VERSION ""

NS_ :

BS_:

BU_: TIRETEMP CART BMS ACC LV INV

BO_ 3221225472 VECTOR__INDEPENDENT_SIG_MSG: 0 Vector__XXX
 SG_ LV_Fault_Count : 0|8@1+ (1,0) [0|0] "" Vector__XXX
 SG_ LV_Pedals_Fault : 0|8@1- (1,0) [0|0] "" Vector__XXX

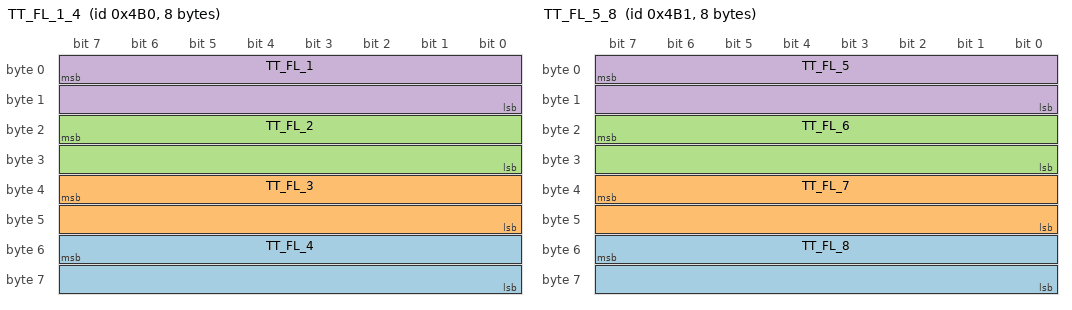
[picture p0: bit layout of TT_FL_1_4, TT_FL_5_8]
BO_ 1200 TT_FL_1_4: 8 TIRETEMP
 SG_ TT_FL_4 : 55|16@0+ (0.1,-100) [-100|6453.5] "temperature:C" Vector__XXX
 SG_ TT_FL_3 : 39|16@0+ (0.1,-100) [-100|6453.5] "temperature:C" Vector__XXX
 SG_ TT_FL_2 : 23|16@0+ (0.1,-100) [-100|6453.5] "temperature:C" Vector__XXX
 SG_ TT_FL_1 : 7|16@0+ (0.1,-100) [-100|6453.5] "temperature:C" Vector__XXX

BO_ 1201 TT_FL_5_8: 8 TIRETEMP
 SG_ TT_FL_8 : 55|16@0+ (0.1,-100) [-100|6453.5] "temperature:C" Vector__XXX
 SG_ TT_FL_7 : 39|16@0+ (0.1,-100) [-100|6453.5] "temperature:C" Vector__XXX
 SG_ TT_FL_6 : 23|16@0+ (0.1,-100) [-100|6453.5] "temperature:C" Vector__XXX
 SG_ TT_FL_5 : 7|16@0+ (0.1,-100) [-100|6453.5] "temperature:C" Vector__XXX

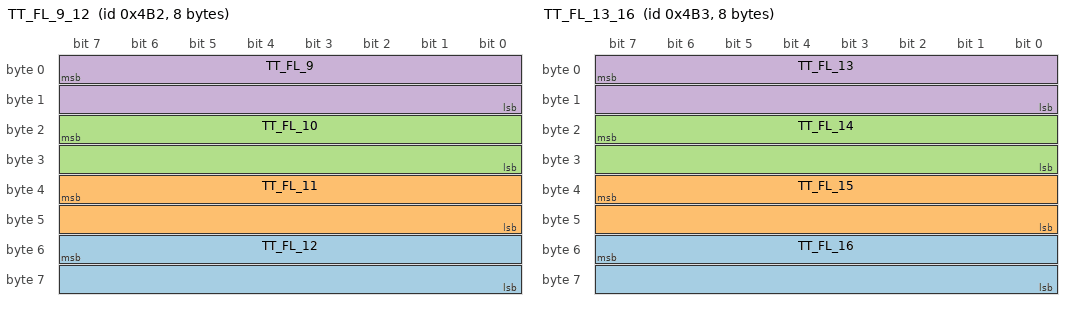
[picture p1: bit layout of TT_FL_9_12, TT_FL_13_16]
BO_ 1202 TT_FL_9_12: 8 TIRETEMP
 SG_ TT_FL_12 : 55|16@0+ (0.1,-100) [-100|6453.5] "temperature:C" Vector__XXX
 SG_ TT_FL_11 : 39|16@0+ (0.1,-100) [-100|6453.5] "temperature:C" Vector__XXX
 SG_ TT_FL_10 : 23|16@0+ (0.1,-100) [-100|6453.5] "temperature:C" Vector__XXX
 SG_ TT_FL_9 : 7|16@0+ (0.1,-100) [-100|6453.5] "temperature:C" Vector__XXX

BO_ 1203 TT_FL_13_16: 8 TIRETEMP
 SG_ TT_FL_16 : 55|16@0+ (0.1,-100) [-100|6453.5] "temperature:C" Vector__XXX
 SG_ TT_FL_15 : 39|16@0+ (0.1,-100) [-100|6453.5] "temperature:C" Vector__XXX
 SG_ TT_FL_14 : 23|16@0+ (0.1,-100) [-100|6453.5] "temperature:C" Vector__XXX
 SG_ TT_FL_13 : 7|16@0+ (0.1,-100) [-100|6453.5] "temperature:C" Vector__XXX

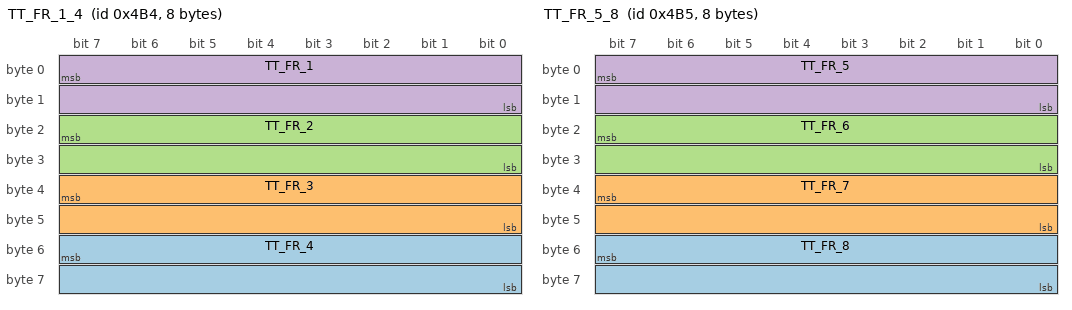
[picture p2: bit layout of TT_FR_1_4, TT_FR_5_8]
BO_ 1204 TT_FR_1_4: 8 TIRETEMP
 SG_ TT_FR_4 : 55|16@0+ (0.1,-100) [-100|6453.5] "temperature:C" Vector__XXX
 SG_ TT_FR_3 : 39|16@0+ (0.1,-100) [-100|6453.5] "temperature:C" Vector__XXX
 SG_ TT_FR_2 : 23|16@0+ (0.1,-100) [-100|6453.5] "temperature:C" Vector__XXX
 SG_ TT_FR_1 : 7|16@0+ (0.1,-100) [-100|6453.5] "temperature:C" Vector__XXX

BO_ 1205 TT_FR_5_8: 8 TIRETEMP
 SG_ TT_FR_8 : 55|16@0+ (0.1,-100) [-100|6453.5] "temperature:C" Vector__XXX
 SG_ TT_FR_7 : 39|16@0+ (0.1,-100) [-100|6453.5] "temperature:C" Vector__XXX
 SG_ TT_FR_6 : 23|16@0+ (0.1,-100) [-100|6453.5] "temperature:C" Vector__XXX
 SG_ TT_FR_5 : 7|16@0+ (0.1,-100) [-100|6453.5] "temperature:C" Vector__XXX

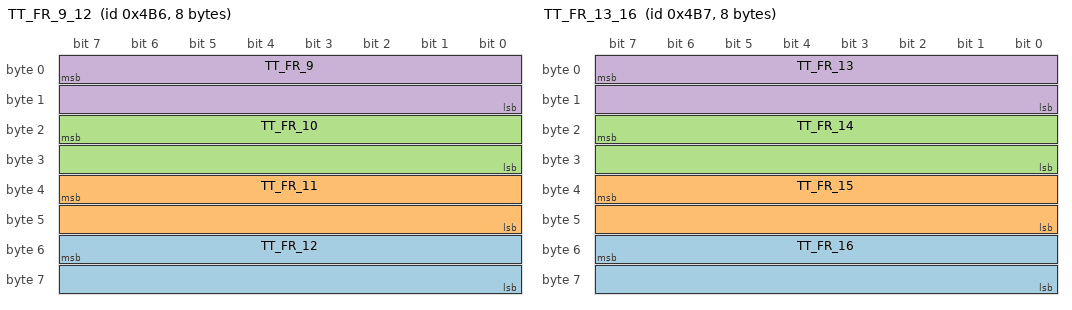
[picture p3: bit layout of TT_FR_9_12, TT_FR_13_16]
BO_ 1206 TT_FR_9_12: 8 TIRETEMP
 SG_ TT_FR_12 : 55|16@0+ (0.1,-100) [-100|6453.5] "temperature:C" Vector__XXX
 SG_ TT_FR_11 : 39|16@0+ (0.1,-100) [-100|6453.5] "temperature:C" Vector__XXX
 SG_ TT_FR_10 : 23|16@0+ (0.1,-100) [-100|6453.5] "temperature:C" Vector__XXX
 SG_ TT_FR_9 : 7|16@0+ (0.1,-100) [-100|6453.5] "temperature:C" Vector__XXX

BO_ 1207 TT_FR_13_16: 8 TIRETEMP
 SG_ TT_FR_16 : 55|16@0+ (0.1,-100) [-100|6453.5] "temperature:C" Vector__XXX
 SG_ TT_FR_15 : 39|16@0+ (0.1,-100) [-100|6453.5] "temperature:C" Vector__XXX
 SG_ TT_FR_14 : 23|16@0+ (0.1,-100) [-100|6453.5] "temperature:C" Vector__XXX
 SG_ TT_FR_13 : 7|16@0+ (0.1,-100) [-100|6453.5] "temperature:C" Vector__XXX

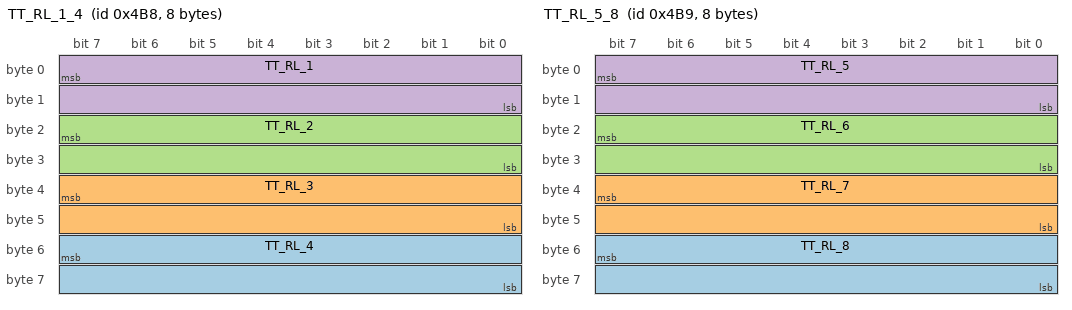
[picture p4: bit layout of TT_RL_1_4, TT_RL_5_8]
BO_ 1208 TT_RL_1_4: 8 TIRETEMP
 SG_ TT_RL_4 : 55|16@0+ (0.1,-100) [-100|6453.5] "temperature:C" Vector__XXX
 SG_ TT_RL_3 : 39|16@0+ (0.1,-100) [-100|6453.5] "temperature:C" Vector__XXX
 SG_ TT_RL_2 : 23|16@0+ (0.1,-100) [-100|6453.5] "temperature:C" Vector__XXX
 SG_ TT_RL_1 : 7|16@0+ (0.1,-100) [-100|6453.5] "temperature:C" Vector__XXX

BO_ 1209 TT_RL_5_8: 8 TIRETEMP
 SG_ TT_RL_8 : 55|16@0+ (0.1,-100) [-100|6453.5] "temperature:C" Vector__XXX
 SG_ TT_RL_7 : 39|16@0+ (0.1,-100) [-100|6453.5] "temperature:C" Vector__XXX
 SG_ TT_RL_6 : 23|16@0+ (0.1,-100) [-100|6453.5] "temperature:C" Vector__XXX
 SG_ TT_RL_5 : 7|16@0+ (0.1,-100) [-100|6453.5] "temperature:C" Vector__XXX

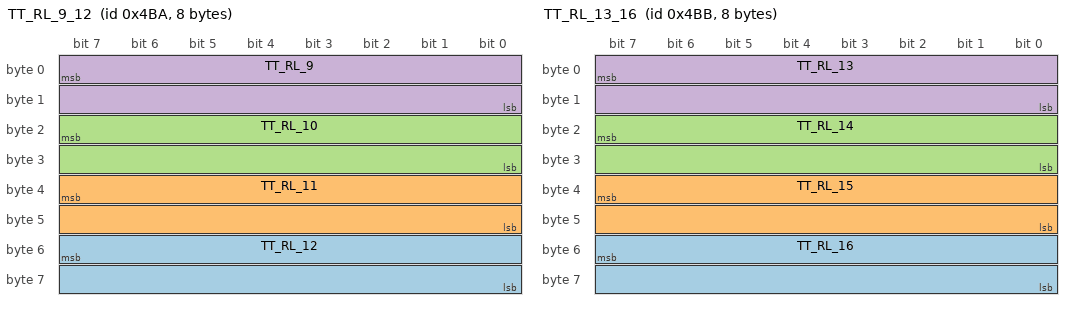
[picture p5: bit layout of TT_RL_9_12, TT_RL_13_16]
BO_ 1210 TT_RL_9_12: 8 TIRETEMP
 SG_ TT_RL_12 : 55|16@0+ (0.1,-100) [-100|6453.5] "temperature:C" Vector__XXX
 SG_ TT_RL_11 : 39|16@0+ (0.1,-100) [-100|6453.5] "temperature:C" Vector__XXX
 SG_ TT_RL_10 : 23|16@0+ (0.1,-100) [-100|6453.5] "temperature:C" Vector__XXX
 SG_ TT_RL_9 : 7|16@0+ (0.1,-100) [-100|6453.5] "temperature:C" Vector__XXX

BO_ 1211 TT_RL_13_16: 8 TIRETEMP
 SG_ TT_RL_16 : 55|16@0+ (0.1,-100) [-100|6453.5] "temperature:C" Vector__XXX
 SG_ TT_RL_15 : 39|16@0+ (0.1,-100) [-100|6453.5] "temperature:C" Vector__XXX
 SG_ TT_RL_14 : 23|16@0+ (0.1,-100) [-100|6453.5] "temperature:C" Vector__XXX
 SG_ TT_RL_13 : 7|16@0+ (0.1,-100) [-100|6453.5] "temperature:C" Vector__XXX

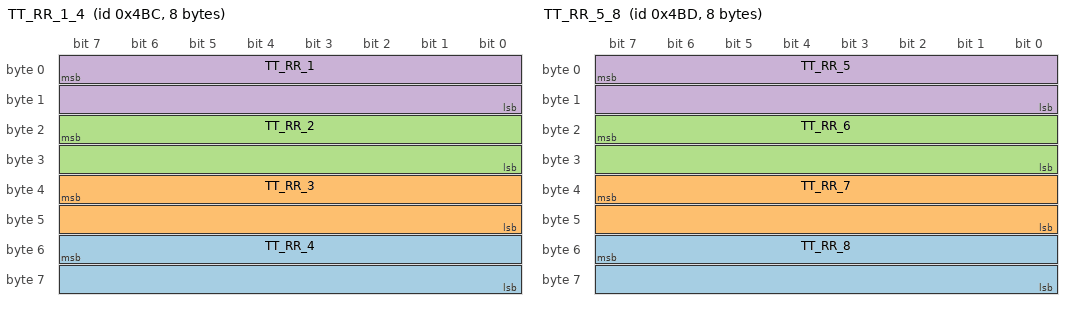
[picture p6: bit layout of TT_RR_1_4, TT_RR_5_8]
BO_ 1212 TT_RR_1_4: 8 TIRETEMP
 SG_ TT_RR_4 : 55|16@0+ (0.1,-100) [-100|6453.5] "temperature:C" Vector__XXX
 SG_ TT_RR_3 : 39|16@0+ (0.1,-100) [-100|6453.5] "temperature:C" Vector__XXX
 SG_ TT_RR_2 : 23|16@0+ (0.1,-100) [-100|6453.5] "temperature:C" Vector__XXX
 SG_ TT_RR_1 : 7|16@0+ (0.1,-100) [-100|6453.5] "temperature:C" Vector__XXX

BO_ 1213 TT_RR_5_8: 8 TIRETEMP
 SG_ TT_RR_8 : 55|16@0+ (0.1,-100) [-100|6453.5] "temperature:C" Vector__XXX
 SG_ TT_RR_7 : 39|16@0+ (0.1,-100) [-100|6453.5] "temperature:C" Vector__XXX
 SG_ TT_RR_6 : 23|16@0+ (0.1,-100) [-100|6453.5] "temperature:C" Vector__XXX
 SG_ TT_RR_5 : 7|16@0+ (0.1,-100) [-100|6453.5] "temperature:C" Vector__XXX

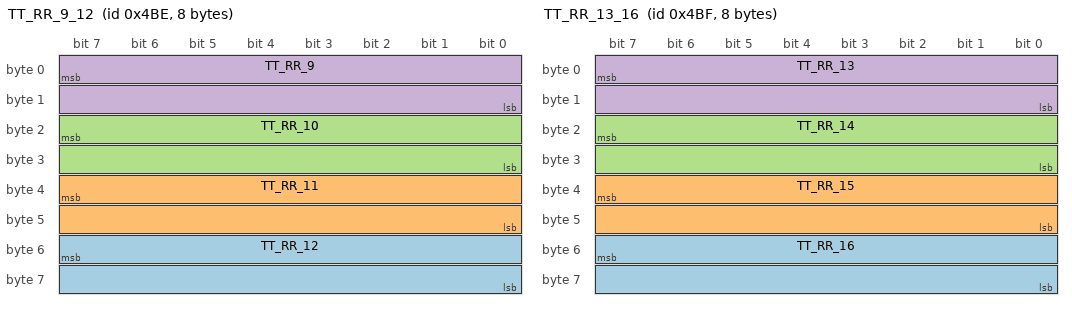
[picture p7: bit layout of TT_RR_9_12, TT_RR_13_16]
BO_ 1214 TT_RR_9_12: 8 TIRETEMP
 SG_ TT_RR_12 : 55|16@0+ (0.1,-100) [-100|6453.5] "temperature:C" Vector__XXX
 SG_ TT_RR_11 : 39|16@0+ (0.1,-100) [-100|6453.5] "temperature:C" Vector__XXX
 SG_ TT_RR_10 : 23|16@0+ (0.1,-100) [-100|6453.5] "temperature:C" Vector__XXX
 SG_ TT_RR_9 : 7|16@0+ (0.1,-100) [-100|6453.5] "temperature:C" Vector__XXX

BO_ 1215 TT_RR_13_16: 8 TIRETEMP
 SG_ TT_RR_16 : 55|16@0+ (0.1,-100) [-100|6453.5] "temperature:C" Vector__XXX
 SG_ TT_RR_15 : 39|16@0+ (0.1,-100) [-100|6453.5] "temperature:C" Vector__XXX
 SG_ TT_RR_14 : 23|16@0+ (0.1,-100) [-100|6453.5] "temperature:C" Vector__XXX
 SG_ TT_RR_13 : 7|16@0+ (0.1,-100) [-100|6453.5] "temperature:C" Vector__XXX

BO_ 4 M004_Charging: 2 LV
 SG_ LV_ACC_Charging_Max_Current : 8|8@1- (1,0) [0|0] "" Vector__XXX
 SG_ LV_ACC_Charging : 0|8@1- (1,0) [0|0] ""  ACC

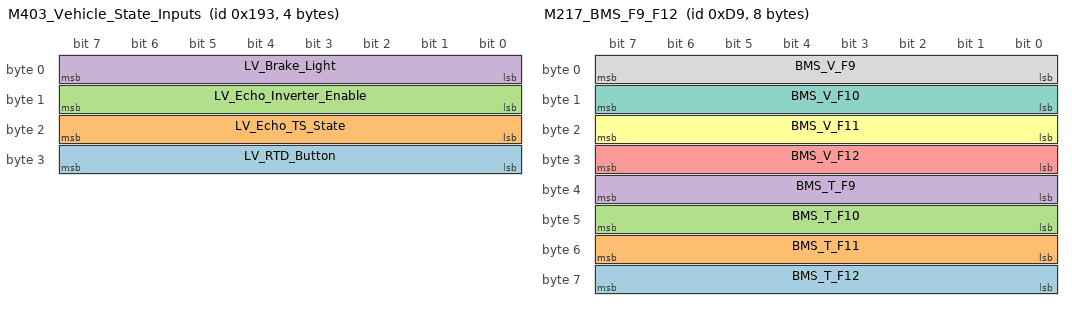
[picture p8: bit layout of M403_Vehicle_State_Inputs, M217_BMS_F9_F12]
BO_ 403 M403_Vehicle_State_Inputs: 4 LV
 SG_ LV_RTD_Button : 24|8@1+ (1,0) [0|0] "" Vector__XXX
 SG_ LV_Echo_TS_State : 16|8@1- (1,0) [0|0] "" Vector__XXX
 SG_ LV_Echo_Inverter_Enable : 8|8@1- (1,0) [0|0] "" Vector__XXX
 SG_ LV_Brake_Light : 0|8@1+ (1,0) [0|0] "" Vector__XXX

BO_ 217 M217_BMS_F9_F12: 8 BMS
 SG_ BMS_T_F12 : 56|8@1+ (0.25,0) [0|63.75] "temperature:C" Vector__XXX
 SG_ BMS_T_F11 : 48|8@1+ (0.25,0) [0|63.75] "temperature:C" Vector__XXX
 SG_ BMS_T_F10 : 40|8@1+ (0.25,0) [0|63.75] "temperature:C" Vector__XXX
 SG_ BMS_T_F9 : 32|8@1+ (0.25,0) [0|63.75] "temperature:C" Vector__XXX
 SG_ BMS_V_F12 : 24|8@1+ (0.01,1.8) [1.8|4.35] "voltage:V" Vector__XXX
 SG_ BMS_V_F11 : 16|8@1+ (0.01,1.8) [1.8|4.35] "voltage:V" Vector__XXX
 SG_ BMS_V_F10 : 8|8@1+ (0.01,1.8) [1.8|4.35] "voltage:V" Vector__XXX
 SG_ BMS_V_F9 : 0|8@1+ (0.01,1.8) [1.8|4.35] "voltage:V" Vector__XXX

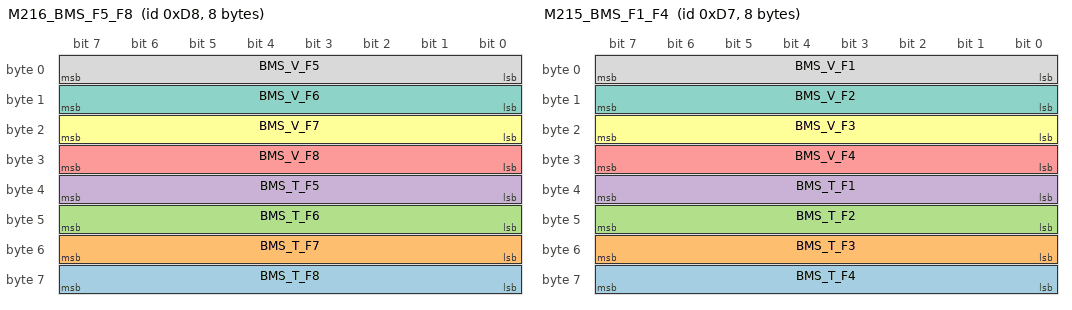
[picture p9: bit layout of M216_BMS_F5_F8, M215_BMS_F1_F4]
BO_ 216 M216_BMS_F5_F8: 8 BMS
 SG_ BMS_T_F8 : 56|8@1+ (0.25,0) [0|63.75] "temperature:C" Vector__XXX
 SG_ BMS_T_F7 : 48|8@1+ (0.25,0) [0|63.75] "temperature:C" Vector__XXX
 SG_ BMS_T_F6 : 40|8@1+ (0.25,0) [0|63.75] "temperature:C" Vector__XXX
 SG_ BMS_T_F5 : 32|8@1+ (0.25,0) [0|63.75] "temperature:C" Vector__XXX
 SG_ BMS_V_F8 : 24|8@1+ (0.01,1.8) [1.8|4.35] "voltage:V" Vector__XXX
 SG_ BMS_V_F7 : 16|8@1+ (0.01,1.8) [1.8|4.35] "voltage:V" Vector__XXX
 SG_ BMS_V_F6 : 8|8@1+ (0.01,1.8) [1.8|4.35] "voltage:V" Vector__XXX
 SG_ BMS_V_F5 : 0|8@1+ (0.01,1.8) [1.8|4.35] "voltage:V" Vector__XXX

BO_ 215 M215_BMS_F1_F4: 8 BMS
 SG_ BMS_T_F4 : 56|8@1+ (0.25,0) [0|63.75] "temperature:C" Vector__XXX
 SG_ BMS_T_F3 : 48|8@1+ (0.25,0) [0|63.75] "temperature:C" Vector__XXX
 SG_ BMS_T_F2 : 40|8@1+ (0.25,0) [0|63.75] "temperature:C" Vector__XXX
 SG_ BMS_T_F1 : 32|8@1+ (0.25,0) [0|63.75] "temperature:C" Vector__XXX
 SG_ BMS_V_F4 : 24|8@1+ (0.01,1.8) [1.8|4.35] "voltage:V" Vector__XXX
 SG_ BMS_V_F3 : 16|8@1+ (0.01,1.8) [1.8|4.35] "voltage:V" Vector__XXX
 SG_ BMS_V_F2 : 8|8@1+ (0.01,1.8) [1.8|4.35] "voltage:V" Vector__XXX
 SG_ BMS_V_F1 : 0|8@1+ (0.01,1.8) [1.8|4.35] "voltage:V" Vector__XXX

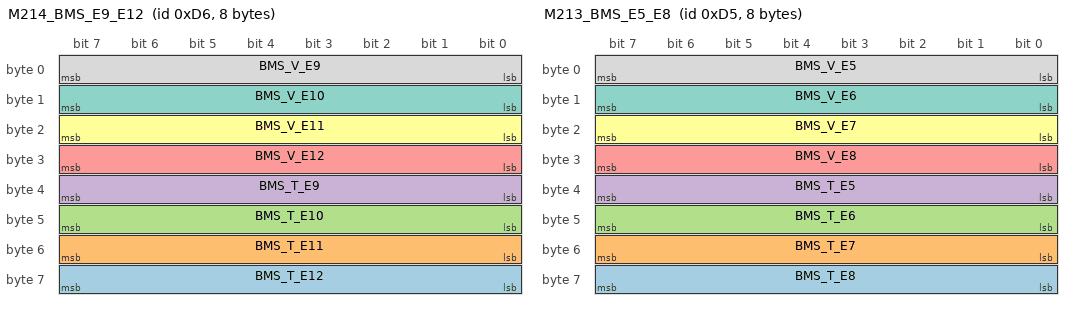
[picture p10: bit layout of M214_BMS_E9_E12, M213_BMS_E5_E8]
BO_ 214 M214_BMS_E9_E12: 8 BMS
 SG_ BMS_T_E12 : 56|8@1+ (0.25,0) [0|63.75] "temperature:C" Vector__XXX
 SG_ BMS_T_E11 : 48|8@1+ (0.25,0) [0|63.75] "temperature:C" Vector__XXX
 SG_ BMS_T_E10 : 40|8@1+ (0.25,0) [0|63.75] "temperature:C" Vector__XXX
 SG_ BMS_T_E9 : 32|8@1+ (0.25,0) [0|63.75] "temperature:C" Vector__XXX
 SG_ BMS_V_E12 : 24|8@1+ (0.01,1.8) [1.8|4.35] "voltage:V" Vector__XXX
 SG_ BMS_V_E11 : 16|8@1+ (0.01,1.8) [1.8|4.35] "voltage:V" Vector__XXX
 SG_ BMS_V_E10 : 8|8@1+ (0.01,1.8) [1.8|4.35] "voltage:V" Vector__XXX
 SG_ BMS_V_E9 : 0|8@1+ (0.01,1.8) [1.8|4.35] "voltage:V" Vector__XXX

BO_ 213 M213_BMS_E5_E8: 8 BMS
 SG_ BMS_T_E8 : 56|8@1+ (0.25,0) [0|63.75] "temperature:C" Vector__XXX
 SG_ BMS_T_E7 : 48|8@1+ (0.25,0) [0|63.75] "temperature:C" Vector__XXX
 SG_ BMS_T_E6 : 40|8@1+ (0.25,0) [0|63.75] "temperature:C" Vector__XXX
 SG_ BMS_T_E5 : 32|8@1+ (0.25,0) [0|63.75] "temperature:C" Vector__XXX
 SG_ BMS_V_E8 : 24|8@1+ (0.01,1.8) [1.8|4.35] "voltage:V" Vector__XXX
 SG_ BMS_V_E7 : 16|8@1+ (0.01,1.8) [1.8|4.35] "voltage:V" Vector__XXX
 SG_ BMS_V_E6 : 8|8@1+ (0.01,1.8) [1.8|4.35] "voltage:V" Vector__XXX
 SG_ BMS_V_E5 : 0|8@1+ (0.01,1.8) [1.8|4.35] "voltage:V" Vector__XXX

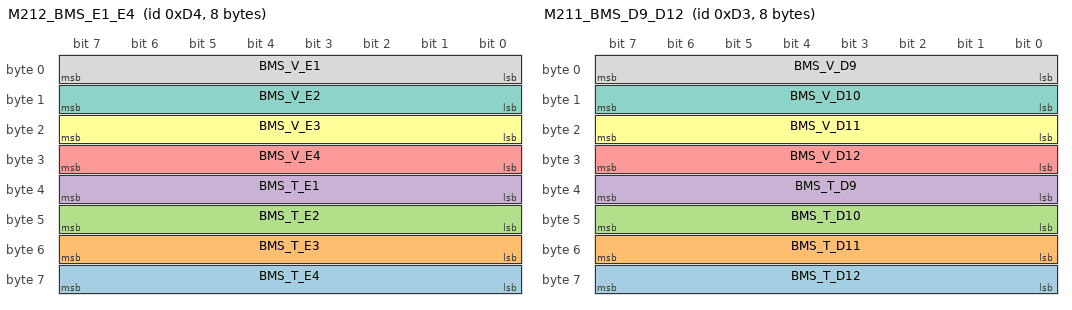
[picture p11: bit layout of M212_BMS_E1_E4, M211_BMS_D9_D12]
BO_ 212 M212_BMS_E1_E4: 8 BMS
 SG_ BMS_T_E4 : 56|8@1+ (0.25,0) [0|63.75] "temperature:C" Vector__XXX
 SG_ BMS_T_E3 : 48|8@1+ (0.25,0) [0|63.75] "temperature:C" Vector__XXX
 SG_ BMS_T_E2 : 40|8@1+ (0.25,0) [0|63.75] "temperature:C" Vector__XXX
 SG_ BMS_T_E1 : 32|8@1+ (0.25,0) [0|63.75] "temperature:C" Vector__XXX
 SG_ BMS_V_E4 : 24|8@1+ (0.01,1.8) [1.8|4.35] "voltage:V" Vector__XXX
 SG_ BMS_V_E3 : 16|8@1+ (0.01,1.8) [1.8|4.35] "voltage:V" Vector__XXX
 SG_ BMS_V_E2 : 8|8@1+ (0.01,1.8) [1.8|4.35] "voltage:V" Vector__XXX
 SG_ BMS_V_E1 : 0|8@1+ (0.01,1.8) [1.8|4.35] "voltage:V" Vector__XXX

BO_ 211 M211_BMS_D9_D12: 8 BMS
 SG_ BMS_T_D12 : 56|8@1+ (0.25,0) [0|63.75] "temperature:C" Vector__XXX
 SG_ BMS_T_D11 : 48|8@1+ (0.25,0) [0|63.75] "temperature:C" Vector__XXX
 SG_ BMS_T_D10 : 40|8@1+ (0.25,0) [0|63.75] "temperature:C" Vector__XXX
 SG_ BMS_T_D9 : 32|8@1+ (0.25,0) [0|63.75] "temperature:C" Vector__XXX
 SG_ BMS_V_D12 : 24|8@1+ (0.01,1.8) [1.8|4.35] "voltage:V" Vector__XXX
 SG_ BMS_V_D11 : 16|8@1+ (0.01,1.8) [1.8|4.35] "voltage:V" Vector__XXX
 SG_ BMS_V_D10 : 8|8@1+ (0.01,1.8) [1.8|4.35] "voltage:V" Vector__XXX
 SG_ BMS_V_D9 : 0|8@1+ (0.01,1.8) [1.8|4.35] "voltage:V" Vector__XXX

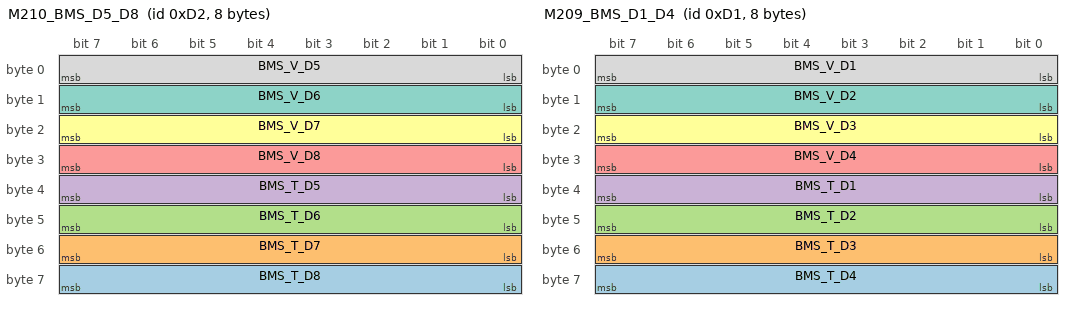
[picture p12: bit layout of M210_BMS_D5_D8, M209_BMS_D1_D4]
BO_ 210 M210_BMS_D5_D8: 8 BMS
 SG_ BMS_T_D8 : 56|8@1+ (0.25,0) [0|63.75] "temperature:C" Vector__XXX
 SG_ BMS_T_D7 : 48|8@1+ (0.25,0) [0|63.75] "temperature:C" Vector__XXX
 SG_ BMS_T_D6 : 40|8@1+ (0.25,0) [0|63.75] "temperature:C" Vector__XXX
 SG_ BMS_T_D5 : 32|8@1+ (0.25,0) [0|63.75] "temperature:C" Vector__XXX
 SG_ BMS_V_D8 : 24|8@1+ (0.01,1.8) [1.8|4.35] "voltage:V" Vector__XXX
 SG_ BMS_V_D7 : 16|8@1+ (0.01,1.8) [1.8|4.35] "voltage:V" Vector__XXX
 SG_ BMS_V_D6 : 8|8@1+ (0.01,1.8) [1.8|4.35] "voltage:V" Vector__XXX
 SG_ BMS_V_D5 : 0|8@1+ (0.01,1.8) [1.8|4.35] "voltage:V" Vector__XXX

BO_ 209 M209_BMS_D1_D4: 8 BMS
 SG_ BMS_T_D4 : 56|8@1+ (0.25,0) [0|63.75] "temperature:C" Vector__XXX
 SG_ BMS_T_D3 : 48|8@1+ (0.25,0) [0|63.75] "temperature:C" Vector__XXX
 SG_ BMS_T_D2 : 40|8@1+ (0.25,0) [0|63.75] "temperature:C" Vector__XXX
 SG_ BMS_T_D1 : 32|8@1+ (0.25,0) [0|63.75] "temperature:C" Vector__XXX
 SG_ BMS_V_D4 : 24|8@1+ (0.01,1.8) [1.8|4.35] "voltage:V" Vector__XXX
 SG_ BMS_V_D3 : 16|8@1+ (0.01,1.8) [1.8|4.35] "voltage:V" Vector__XXX
 SG_ BMS_V_D2 : 8|8@1+ (0.01,1.8) [1.8|4.35] "voltage:V" Vector__XXX
 SG_ BMS_V_D1 : 0|8@1+ (0.01,1.8) [1.8|4.35] "voltage:V" Vector__XXX

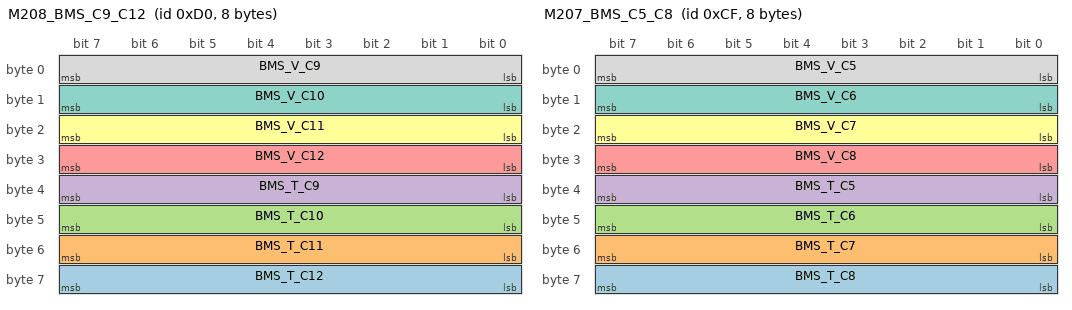
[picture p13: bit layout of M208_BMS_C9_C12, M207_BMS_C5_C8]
BO_ 208 M208_BMS_C9_C12: 8 BMS
 SG_ BMS_T_C12 : 56|8@1+ (0.25,0) [0|63.75] "temperature:C" Vector__XXX
 SG_ BMS_T_C11 : 48|8@1+ (0.25,0) [0|63.75] "temperature:C" Vector__XXX
 SG_ BMS_T_C10 : 40|8@1+ (0.25,0) [0|63.75] "temperature:C" Vector__XXX
 SG_ BMS_T_C9 : 32|8@1+ (0.25,0) [0|63.75] "temperature:C" Vector__XXX
 SG_ BMS_V_C12 : 24|8@1+ (0.01,1.8) [1.8|4.35] "voltage:V" Vector__XXX
 SG_ BMS_V_C11 : 16|8@1+ (0.01,1.8) [1.8|4.35] "voltage:V" Vector__XXX
 SG_ BMS_V_C10 : 8|8@1+ (0.01,1.8) [1.8|4.35] "voltage:V" Vector__XXX
 SG_ BMS_V_C9 : 0|8@1+ (0.01,1.8) [1.8|4.35] "voltage:V" Vector__XXX

BO_ 207 M207_BMS_C5_C8: 8 BMS
 SG_ BMS_T_C8 : 56|8@1+ (0.25,0) [0|63.75] "temperature:C" Vector__XXX
 SG_ BMS_T_C7 : 48|8@1+ (0.25,0) [0|63.75] "temperature:C" Vector__XXX
 SG_ BMS_T_C6 : 40|8@1+ (0.25,0) [0|63.75] "temperature:C" Vector__XXX
 SG_ BMS_T_C5 : 32|8@1+ (0.25,0) [0|63.75] "temperature:C" Vector__XXX
 SG_ BMS_V_C8 : 24|8@1+ (0.01,1.8) [1.8|4.35] "voltage:V" Vector__XXX
 SG_ BMS_V_C7 : 16|8@1+ (0.01,1.8) [1.8|4.35] "voltage:V" Vector__XXX
 SG_ BMS_V_C6 : 8|8@1+ (0.01,1.8) [1.8|4.35] "voltage:V" Vector__XXX
 SG_ BMS_V_C5 : 0|8@1+ (0.01,1.8) [1.8|4.35] "voltage:V" Vector__XXX

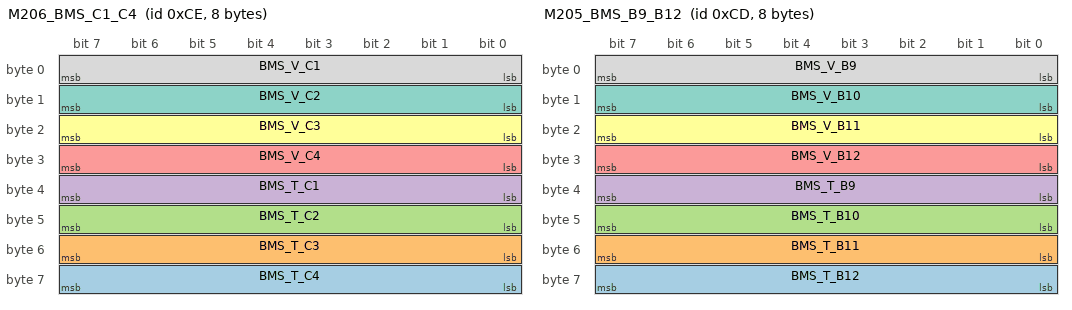
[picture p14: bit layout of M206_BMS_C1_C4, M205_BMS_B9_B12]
BO_ 206 M206_BMS_C1_C4: 8 BMS
 SG_ BMS_T_C4 : 56|8@1+ (0.25,0) [0|63.75] "temperature:C" Vector__XXX
 SG_ BMS_T_C3 : 48|8@1+ (0.25,0) [0|63.75] "temperature:C" Vector__XXX
 SG_ BMS_T_C2 : 40|8@1+ (0.25,0) [0|63.75] "temperature:C" Vector__XXX
 SG_ BMS_T_C1 : 32|8@1+ (0.25,0) [0|63.75] "temperature:C" Vector__XXX
 SG_ BMS_V_C4 : 24|8@1+ (0.01,1.8) [1.8|4.35] "voltage:V" Vector__XXX
 SG_ BMS_V_C3 : 16|8@1+ (0.01,1.8) [1.8|4.35] "voltage:V" Vector__XXX
 SG_ BMS_V_C2 : 8|8@1+ (0.01,1.8) [1.8|4.35] "voltage:V" Vector__XXX
 SG_ BMS_V_C1 : 0|8@1+ (0.01,1.8) [1.8|4.35] "voltage:V" Vector__XXX

BO_ 205 M205_BMS_B9_B12: 8 BMS
 SG_ BMS_T_B12 : 56|8@1+ (0.25,0) [0|63.75] "temperature:C" Vector__XXX
 SG_ BMS_T_B11 : 48|8@1+ (0.25,0) [0|63.75] "temperature:C" Vector__XXX
 SG_ BMS_T_B10 : 40|8@1+ (0.25,0) [0|63.75] "temperature:C" Vector__XXX
 SG_ BMS_T_B9 : 32|8@1+ (0.25,0) [0|63.75] "temperature:C" Vector__XXX
 SG_ BMS_V_B12 : 24|8@1+ (0.01,1.8) [1.8|4.35] "voltage:V" Vector__XXX
 SG_ BMS_V_B11 : 16|8@1+ (0.01,1.8) [1.8|4.35] "voltage:V" Vector__XXX
 SG_ BMS_V_B10 : 8|8@1+ (0.01,1.8) [1.8|4.35] "voltage:V" Vector__XXX
 SG_ BMS_V_B9 : 0|8@1+ (0.01,1.8) [1.8|4.35] "voltage:V" Vector__XXX

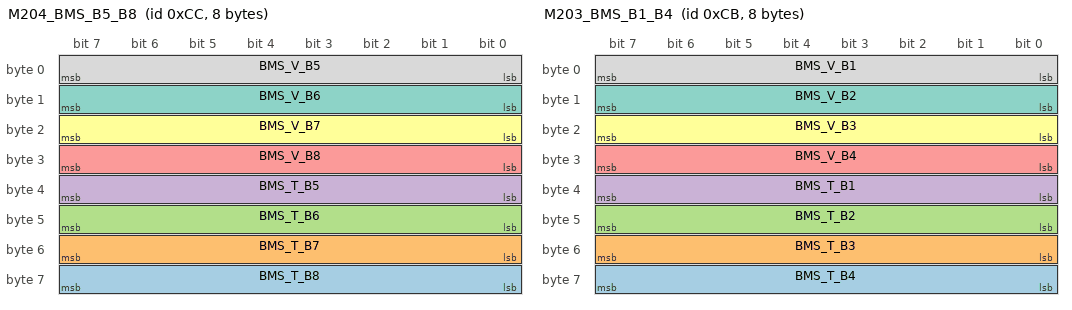
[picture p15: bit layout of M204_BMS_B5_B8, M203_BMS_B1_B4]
BO_ 204 M204_BMS_B5_B8: 8 BMS
 SG_ BMS_T_B8 : 56|8@1+ (0.25,0) [0|63.75] "temperature:C" Vector__XXX
 SG_ BMS_T_B7 : 48|8@1+ (0.25,0) [0|63.75] "temperature:C" Vector__XXX
 SG_ BMS_T_B6 : 40|8@1+ (0.25,0) [0|63.75] "temperature:C" Vector__XXX
 SG_ BMS_T_B5 : 32|8@1+ (0.25,0) [0|63.75] "temperature:C" Vector__XXX
 SG_ BMS_V_B8 : 24|8@1+ (0.01,1.8) [1.8|4.35] "voltage:V" Vector__XXX
 SG_ BMS_V_B7 : 16|8@1+ (0.01,1.8) [1.8|4.35] "voltage:V" Vector__XXX
 SG_ BMS_V_B6 : 8|8@1+ (0.01,1.8) [1.8|4.35] "voltage:V" Vector__XXX
 SG_ BMS_V_B5 : 0|8@1+ (0.01,1.8) [1.8|4.35] "voltage:V" Vector__XXX

BO_ 203 M203_BMS_B1_B4: 8 BMS
 SG_ BMS_T_B4 : 56|8@1+ (0.25,0) [0|63.75] "temperature:C" Vector__XXX
 SG_ BMS_T_B3 : 48|8@1+ (0.25,0) [0|63.75] "temperature:C" Vector__XXX
 SG_ BMS_T_B2 : 40|8@1+ (0.25,0) [0|63.75] "temperature:C" Vector__XXX
 SG_ BMS_T_B1 : 32|8@1+ (0.25,0) [0|63.75] "temperature:C" Vector__XXX
 SG_ BMS_V_B4 : 24|8@1+ (0.01,1.8) [1.8|4.35] "voltage:V" Vector__XXX
 SG_ BMS_V_B3 : 16|8@1+ (0.01,1.8) [1.8|4.35] "voltage:V" Vector__XXX
 SG_ BMS_V_B2 : 8|8@1+ (0.01,1.8) [1.8|4.35] "voltage:V" Vector__XXX
 SG_ BMS_V_B1 : 0|8@1+ (0.01,1.8) [1.8|4.35] "voltage:V" Vector__XXX

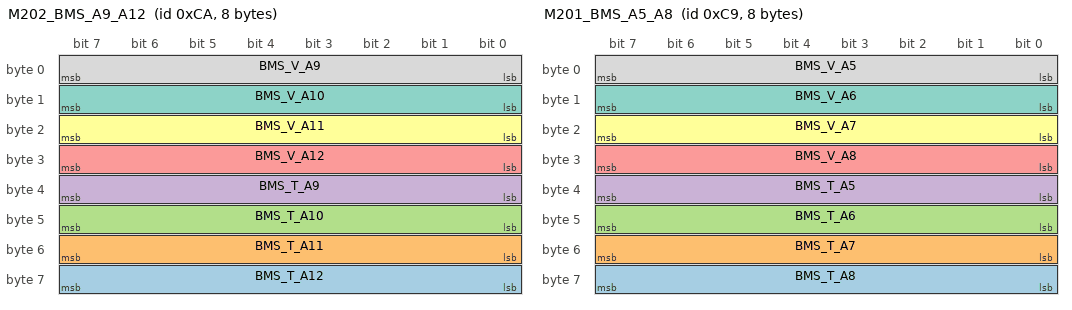
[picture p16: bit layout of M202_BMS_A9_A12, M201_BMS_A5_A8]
BO_ 202 M202_BMS_A9_A12: 8 BMS
 SG_ BMS_T_A12 : 56|8@1+ (0.25,0) [0|63.75] "temperature:C" Vector__XXX
 SG_ BMS_T_A11 : 48|8@1+ (0.25,0) [0|63.75] "temperature:C" Vector__XXX
 SG_ BMS_T_A10 : 40|8@1+ (0.25,0) [0|63.75] "temperature:C" Vector__XXX
 SG_ BMS_T_A9 : 32|8@1+ (0.25,0) [0|63.75] "temperature:C" Vector__XXX
 SG_ BMS_V_A12 : 24|8@1+ (0.01,1.8) [1.8|4.35] "voltage:V" Vector__XXX
 SG_ BMS_V_A11 : 16|8@1+ (0.01,1.8) [1.8|4.35] "voltage:V" Vector__XXX
 SG_ BMS_V_A10 : 8|8@1+ (0.01,1.8) [1.8|4.35] "voltage:V" Vector__XXX
 SG_ BMS_V_A9 : 0|8@1+ (0.01,1.8) [1.8|4.35] "voltage:V" Vector__XXX

BO_ 201 M201_BMS_A5_A8: 8 BMS
 SG_ BMS_T_A8 : 56|8@1+ (0.25,0) [0|63.75] "temperature:C" Vector__XXX
 SG_ BMS_T_A7 : 48|8@1+ (0.25,0) [0|63.75] "temperature:C" Vector__XXX
 SG_ BMS_T_A6 : 40|8@1+ (0.25,0) [0|63.75] "temperature:C" Vector__XXX
 SG_ BMS_T_A5 : 32|8@1+ (0.25,0) [0|63.75] "temperature:C" Vector__XXX
 SG_ BMS_V_A8 : 24|8@1+ (0.01,1.8) [1.8|4.35] "voltage:V" Vector__XXX
 SG_ BMS_V_A7 : 16|8@1+ (0.01,1.8) [1.8|4.35] "voltage:V" Vector__XXX
 SG_ BMS_V_A6 : 8|8@1+ (0.01,1.8) [1.8|4.35] "voltage:V" Vector__XXX
 SG_ BMS_V_A5 : 0|8@1+ (0.01,1.8) [1.8|4.35] "voltage:V" Vector__XXX

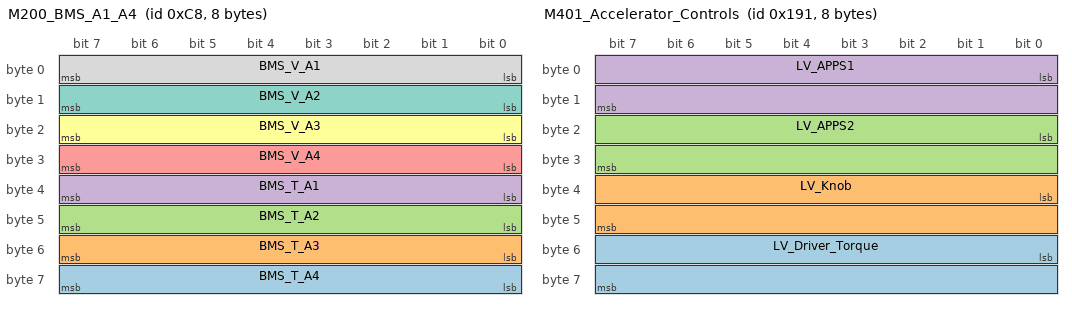
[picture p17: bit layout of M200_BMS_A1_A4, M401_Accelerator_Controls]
BO_ 200 M200_BMS_A1_A4: 8 BMS
 SG_ BMS_T_A4 : 56|8@1+ (0.25,0) [0|63.75] "temperature:C" Vector__XXX
 SG_ BMS_T_A3 : 48|8@1+ (0.25,0) [0|63.75] "temperature:C" Vector__XXX
 SG_ BMS_T_A2 : 40|8@1+ (0.25,0) [0|63.75] "temperature:C" Vector__XXX
 SG_ BMS_T_A1 : 32|8@1+ (0.25,0) [0|63.75] "temperature:C" Vector__XXX
 SG_ BMS_V_A4 : 24|8@1+ (0.01,1.8) [1.8|4.35] "voltage:V" Vector__XXX
 SG_ BMS_V_A3 : 16|8@1+ (0.01,1.8) [1.8|4.35] "voltage:V" Vector__XXX
 SG_ BMS_V_A2 : 8|8@1+ (0.01,1.8) [1.8|4.35] "voltage:V" Vector__XXX
 SG_ BMS_V_A1 : 0|8@1+ (0.01,1.8) [1.8|4.35] "voltage:V" Vector__XXX

BO_ 3 M003_DCDC_Enable: 1 LV
 SG_ LV_ACC_DCDC_Enable : 0|8@1- (1,0) [0|0] ""  ACC

BO_ 2 M002_TS_State: 1 ACC
 SG_ ACC_TS_State : 0|8@1- (1,0) [0|0] ""  LV

BO_ 1 M001_Vehicle_State: 1 LV
 SG_ LV_Vehicle_State : 0|8@1- (1,0) [0|0] "" Vector__XXX

BO_ 402 M402_Brakes_Faults_Display: 7 LV
 SG_ LV_Knob_Tick : 48|8@1+ (0.1,0) [0|25.5] "" Vector__XXX
 SG_ LV_Momentary_Both_Pedals : 47|1@1+ (1,0) [0|1] "" Vector__XXX
 SG_ LV_Momentary_APPS_Implausibility : 46|1@1+ (1,0) [0|1] "" Vector__XXX
 SG_ LV_Momentary_BPT_Upper : 45|1@1+ (1,0) [0|1] "" Vector__XXX
 SG_ LV_Momentary_BPT_Lower : 44|1@1+ (1,0) [0|1] "" Vector__XXX
 SG_ LV_Momentary_APPS2_Upper : 43|1@1+ (1,0) [0|1] "" Vector__XXX
 SG_ LV_Momentary_APPS2_Lower : 42|1@1+ (1,0) [0|1] "" Vector__XXX
 SG_ LV_Momentary_APPS1_Upper : 41|1@1+ (1,0) [0|1] "" Vector__XXX
 SG_ LV_Momentary_APPS1_Lower : 40|1@1+ (1,0) [0|1] "" Vector__XXX
 SG_ LV_Fault_Both_Pedals : 39|1@1+ (1,0) [0|1] "" Vector__XXX
 SG_ LV_Fault_APPS_Implausibility : 38|1@1+ (1,0) [0|1] "" Vector__XXX
 SG_ LV_Fault_BPT_Upper : 37|1@1+ (1,0) [0|1] "" Vector__XXX
 SG_ LV_Fault_BPT_Lower : 36|1@1+ (1,0) [0|1] "" Vector__XXX
 SG_ LV_Fault_APPS2_Upper : 35|1@1+ (1,0) [0|1] "" Vector__XXX
 SG_ LV_Fault_APPS2_Lower : 34|1@1+ (1,0) [0|1] "" Vector__XXX
 SG_ LV_Fault_APPS1_Upper : 33|1@1+ (1,0) [0|1] "" Vector__XXX
 SG_ LV_Fault_APPS1_Lower : 32|1@1+ (1,0) [0|1] "" Vector__XXX
 SG_ LV_BPT_Front : 16|16@1+ (1,0) [0|0] "" Vector__XXX
 SG_ LV_BPT_Rear : 0|16@1+ (1,0) [0|0] "" Vector__XXX

BO_ 401 M401_Accelerator_Controls: 8 LV
 SG_ LV_Driver_Torque : 48|16@1- (0.1,0) [-3276.8|3276.7] "torque:N.m" Vector__XXX
 SG_ LV_Knob : 32|16@1+ (1,0) [0|0] "" Vector__XXX
 SG_ LV_APPS2 : 16|16@1+ (1,0) [0|0] "" Vector__XXX
 SG_ LV_APPS1 : 0|16@1+ (1,0) [0|0] "" Vector__XXX

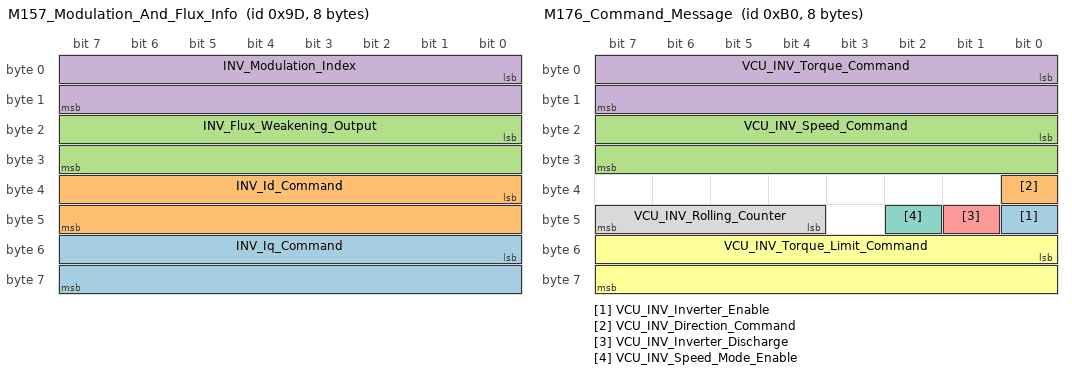
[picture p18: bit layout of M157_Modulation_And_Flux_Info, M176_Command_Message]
BO_ 157 M157_Modulation_And_Flux_Info: 8 INV
 SG_ INV_Iq_Command : 48|16@1- (0.1,0) [-3276.8|3276.7] "current:A" Vector__XXX
 SG_ INV_Id_Command : 32|16@1- (0.1,0) [-3276.8|3276.7] "current:A" Vector__XXX
 SG_ INV_Flux_Weakening_Output : 16|16@1- (0.1,0) [-3276.8|3276.7] "current:A" Vector__XXX
 SG_ INV_Modulation_Index : 0|16@1- (0.0001,0) [-3.2768|3.2767] "" Vector__XXX

BO_ 156 M156_Torque_And_Timer_Info: 8 INV
 SG_ INV_Power_On_Timer : 32|32@1+ (0.003,0) [0|12884800] "time:second" Vector__XXX
 SG_ INV_Torque_Feedback : 16|16@1- (0.1,0) [-3276.8|3276.7] "torque:N.m" Vector__XXX
 SG_ INV_Commanded_Torque : 0|16@1- (0.1,0) [-3276.8|3276.7] "torque:N.m" Vector__XXX

BO_ 178 M178_Read_Write_Param_Response: 8 INV
 SG_ INV_Parameter_Response_Write_OK : 16|1@1+ (1,0) [0|1] "" Vector__XXX
 SG_ INV_Parameter_Response_Data : 32|16@1- (1,0) [-32768|32767] "" Vector__XXX
 SG_ INV_Parameter_Response_Addr : 0|16@1+ (1,0) [0|65535] "" Vector__XXX

BO_ 177 M177_Read_Write_Param_Command: 8 Vector__XXX
 SG_ VCU_INV_Parameter_Data : 32|16@1- (1,0) [-32768|32767] "" Vector__XXX
 SG_ VCU_INV_Parameter_RW_Command : 16|1@1+ (1,0) [0|1] "" Vector__XXX
 SG_ VCU_INV_Parameter_Address : 0|16@1+ (1,0) [0|65535] "" Vector__XXX

BO_ 176 M176_Command_Message: 8 LV
 SG_ VCU_INV_Inverter_Enable : 40|1@1+ (1,0) [0|1] "" Vector__XXX
 SG_ VCU_INV_Direction_Command : 32|1@1+ (1,0) [0|1] "" Vector__XXX
 SG_ VCU_INV_Speed_Command : 16|16@1- (1,0) [-32768|32767] "angular_speed:rpm" Vector__XXX
 SG_ VCU_INV_Torque_Command : 0|16@1- (0.1,0) [-3276.8|3276.7] "torque:N.m" Vector__XXX
 SG_ VCU_INV_Inverter_Discharge : 41|1@1+ (1,0) [0|1] "" Vector__XXX
 SG_ VCU_INV_Torque_Limit_Command : 48|16@1- (0.1,0) [-3276.8|3276.7] "torque:N.m" Vector__XXX
 SG_ VCU_INV_Speed_Mode_Enable : 42|1@1+ (1,0) [0|1] "" Vector__XXX
 SG_ VCU_INV_Rolling_Counter : 44|4@1+ (1,0) [0|15] "" Vector__XXX

BO_ 155 M155_Fault_Codes: 8 INV
 SG_ INV_Run_Fault_Hi : 48|16@1+ (1,0) [0|65535] "" Vector__XXX
 SG_ INV_Post_Fault_Hi : 16|16@1+ (1,0) [0|65535] "" Vector__XXX
 SG_ INV_Run_Fault_Lo : 32|16@1+ (1,0) [0|65535] "" Vector__XXX
 SG_ INV_Post_Fault_Lo : 0|16@1+ (1,0) [0|65535] "" Vector__XXX

BO_ 154 M154_Internal_States: 8 INV
 SG_ INV_Direction_Command : 56|1@1+ (1,0) [0|1] "" Vector__XXX
 SG_ INV_Inverter_Enable_State : 48|1@1+ (1,0) [0|1] ""  LV
 SG_ INV_Relay_3_Status : 26|1@1+ (1,0) [0|1] "" Vector__XXX
 SG_ INV_Relay_4_Status : 27|1@1+ (1,0) [0|1] "" Vector__XXX
 SG_ INV_Relay_2_Status : 25|1@1+ (1,0) [0|1] "" Vector__XXX
 SG_ INV_Inverter_Run_Mode : 32|1@1+ (1,0) [0|1] "" Vector__XXX
 SG_ INV_Inverter_Command_Mode : 40|1@1+ (1,0) [0|1] "" Vector__XXX
 SG_ INV_Relay_1_Status : 24|1@1+ (1,0) [0|1] "" Vector__XXX
 SG_ INV_Inverter_State : 16|8@1+ (1,0) [0|255] "" Vector__XXX
 SG_ INV_VSM_State : 0|8@1+ (1,0) [0|15] "" Vector__XXX
 SG_ INV_Inverter_Enable_Lockout : 55|1@1+ (1,0) [0|1] "" Vector__XXX
 SG_ INV_Inverter_Discharge_State : 37|3@1+ (1,0) [0|7] "" Vector__XXX
 SG_ INV_Relay_5_Status : 28|1@1+ (1,0) [0|1] "" Vector__XXX
 SG_ INV_Relay_6_Status : 29|1@1+ (1,0) [0|1] "" Vector__XXX
 SG_ INV_BMS_Active : 57|1@1+ (1,0) [0|1] "" Vector__XXX
 SG_ INV_BMS_Torque_Limiting : 58|1@1+ (1,0) [0|1] "" Vector__XXX
 SG_ INV_PWM_Frequency : 8|8@1+ (1,0) [0|255] "" Vector__XXX
 SG_ INV_Limit_Max_Speed : 59|1@1+ (1,0) [0|1] "" Vector__XXX
 SG_ INV_Limit_Hot_Spot : 60|1@1+ (1,0) [0|1] "" Vector__XXX
 SG_ INV_Low_Speed_Limiting : 61|1@1+ (1,0) [0|1] "" Vector__XXX
 SG_ INV_Rolling_Counter : 44|4@1+ (1,0) [0|15] "" Vector__XXX
 SG_ INV_Limit_Coolant_Derating : 62|1@1+ (1,0) [0|1] "" Vector__XXX
 SG_ INV_Self_Sensing_Assist_Enable : 33|1@1+ (1,0) [0|1] "" Vector__XXX
 SG_ INV_Limit_Stall_Burst_Model : 63|1@1+ (1,0) [0|1] "" Vector__XXX
 SG_ INV_Burst_Model_Mode : 49|1@1+ (1,0) [0|1] "" Vector__XXX
 SG_ INV_Key_Switch_Start_Status : 54|1@1+ (1,0) [0|1] "" Vector__XXX

BO_ 153 M153_Internal_Voltages: 8 INV
 SG_ INV_Ref_Voltage_12_0 : 48|16@1- (0.01,0) [-327.68|327.67] "voltage:V" Vector__XXX
 SG_ INV_Ref_Voltage_5_0 : 32|16@1- (0.01,0) [-327.68|327.67] "voltage:V" Vector__XXX
 SG_ INV_Ref_Voltage_2_5 : 16|16@1- (0.01,0) [-327.68|327.67] "voltage:V" Vector__XXX
 SG_ INV_Ref_Voltage_1_5 : 0|16@1- (0.01,0) [-327.68|327.67] "voltage:V" Vector__XXX

BO_ 152 M152_Flux_ID_IQ_Info: 8 INV
 SG_ INV_Iq : 48|16@1- (0.1,0) [-3276.8|3276.7] "current:A" Vector__XXX
 SG_ INV_Id : 32|16@1- (0.1,0) [-3276.8|3276.7] "current:A" Vector__XXX
 SG_ INV_Vq_ff : 16|16@1- (0.1,0) [-3276.7|3276.7] "voltage:V" Vector__XXX
 SG_ INV_Vd_ff : 0|16@1- (0.1,0) [-3276.7|3276.7] "voltage:V" Vector__XXX

BO_ 151 M151_Voltage_Info: 8 INV
 SG_ INV_VBC_Vq_Voltage : 48|16@1- (0.1,0) [-3276.8|3276.7] "voltage:V" Vector__XXX
 SG_ INV_VAB_Vd_Voltage : 32|16@1- (0.1,0) [-3276.8|3276.7] "voltage:V" Vector__XXX
 SG_ INV_Output_Voltage : 16|16@1- (0.1,0) [-3276.8|3276.7] "voltage:V" Vector__XXX
 SG_ INV_DC_Bus_Voltage : 0|16@1- (0.1,0) [-3276.8|3276.7] "voltage:V" Vector__XXX

BO_ 150 M150_Current_Info: 8 INV
 SG_ INV_DC_Bus_Current : 48|16@1- (0.1,0) [-3276.8|3276.7] "current:A" Vector__XXX
 SG_ INV_Phase_C_Current : 32|16@1- (0.1,0) [-3276.8|3276.7] "current:A" Vector__XXX
 SG_ INV_Phase_B_Current : 16|16@1- (0.1,0) [-3276.8|3276.7] "current:A" Vector__XXX
 SG_ INV_Phase_A_Current : 0|16@1- (0.1,0) [-3276.8|3276.7] "current:A" Vector__XXX

BO_ 149 M149_Motor_Position_Info: 8 INV
 SG_ INV_Delta_Resolver_Filtered : 48|16@1- (0.1,0) [-3276.8|3276.7] "angle:deg" Vector__XXX
 SG_ INV_Electrical_Output_Frequency : 32|16@1- (0.1,0) [-3276.8|3276.7] "frequency:Hz" Vector__XXX
 SG_ INV_Motor_Speed : 16|16@1- (1,0) [-32768|32767] "angular_speed:rpm" Vector__XXX
 SG_ INV_Motor_Angle_Electrical : 0|16@1+ (0.1,0) [0|6553.5] "angle:deg" Vector__XXX

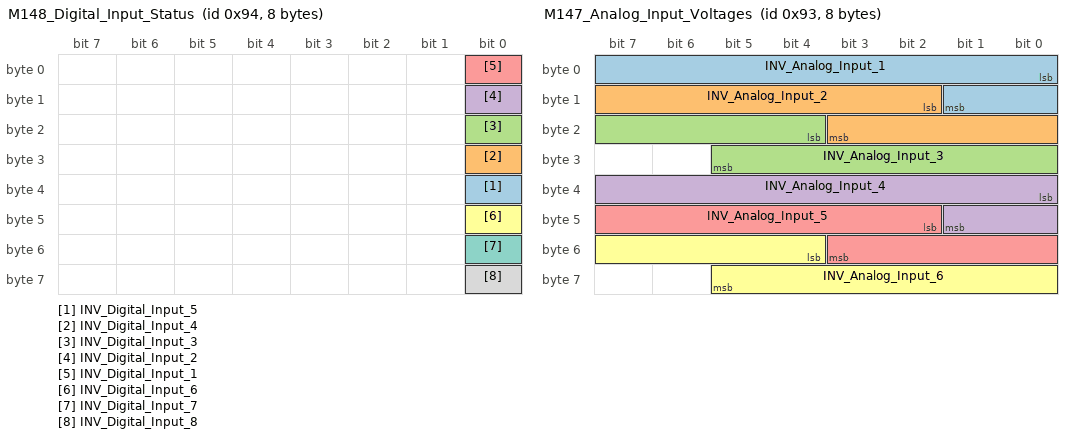
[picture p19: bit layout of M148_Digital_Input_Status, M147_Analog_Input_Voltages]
BO_ 148 M148_Digital_Input_Status: 8 INV
 SG_ INV_Digital_Input_5 : 32|1@1+ (1,0) [0|1] "" Vector__XXX
 SG_ INV_Digital_Input_4 : 24|1@1+ (1,0) [0|1] "" Vector__XXX
 SG_ INV_Digital_Input_3 : 16|1@1+ (1,0) [0|1] "" Vector__XXX
 SG_ INV_Digital_Input_2 : 8|1@1+ (1,0) [0|1] "" Vector__XXX
 SG_ INV_Digital_Input_1 : 0|1@1+ (1,0) [0|1] "" Vector__XXX
 SG_ INV_Digital_Input_6 : 40|1@1+ (1,0) [0|1] "" Vector__XXX
 SG_ INV_Digital_Input_7 : 48|1@1+ (1,0) [0|1] "" Vector__XXX
 SG_ INV_Digital_Input_8 : 56|1@1+ (1,0) [0|1] "" Vector__XXX

BO_ 147 M147_Analog_Input_Voltages: 8 INV
 SG_ INV_Analog_Input_1 : 0|10@1+ (0.01,0) [0|10.23] "voltage:V" Vector__XXX
 SG_ INV_Analog_Input_2 : 10|10@1+ (0.01,0) [0|10.23] "voltage:V" Vector__XXX
 SG_ INV_Analog_Input_3 : 20|10@1+ (0.01,0) [0|10.23] "voltage:V" Vector__XXX
 SG_ INV_Analog_Input_4 : 32|10@1+ (0.01,0) [0|10.23] "voltage:V" Vector__XXX
 SG_ INV_Analog_Input_5 : 42|10@1+ (0.01,0) [0|10.23] "voltage:V" Vector__XXX
 SG_ INV_Analog_Input_6 : 52|10@1+ (0.01,0) [0|10.23] "voltage:V" Vector__XXX

BO_ 146 M146_Temperature_Set_3: 8 INV
 SG_ INV_Torque_Shudder : 48|16@1- (0.1,0) [-3276.8|3276.7] "torque:N.m" Vector__XXX
 SG_ INV_Motor_Temp : 32|16@1- (0.1,0) [-3276.8|3276.7] "temperature:C" Vector__XXX
 SG_ INV_Hot_Spot_Temp : 16|16@1- (0.1,0) [-3276.8|3276.7] "temperature:C" Vector__XXX
 SG_ INV_Coolant_Temp : 0|16@1- (0.1,0) [-3276.8|3276.7] "temperature:C" Vector__XXX

BO_ 145 M145_Temperature_Set_2: 8 INV
 SG_ INV_RTD2_Temperature : 32|16@1- (0.1,0) [-3276.8|3276.7] "temperature:C" Vector__XXX
 SG_ INV_RTD1_Temperature : 16|16@1- (0.1,0) [-3276.8|3276.7] "temperature:C" Vector__XXX
 SG_ INV_Control_Board_Temp : 0|16@1- (0.1,0) [-3276.8|3276.7] "temperature:C" Vector__XXX
 SG_ INV_Stall_Burst_Model_Temp : 48|16@1- (0.1,0) [-3276.8|3276.7] "temperature:C" Vector__XXX

BO_ 144 M144_Temperature_Set_1: 8 INV
 SG_ INV_Gate_Driver_Board_Temp : 48|16@1- (0.1,0) [-3276.8|3276.7] "temperature:C" Vector__XXX
 SG_ INV_Module_C_Temp : 32|16@1- (0.1,0) [-3276.8|3276.7] "temperature:C" Vector__XXX
 SG_ INV_Module_B_Temp : 16|16@1- (0.1,0) [-3276.8|3276.7] "temperature:C" Vector__XXX
 SG_ INV_Module_A_Temp : 0|16@1- (0.1,0) [-3276.8|3276.7] "temperature:C" Vector__XXX

BO_ 158 M158_Firmware_Info: 8 INV
 SG_ INV_Project_Code_EEP_Ver : 0|16@1+ (1,0) [0|65535] "" Vector__XXX
 SG_ INV_SW_Version : 16|16@1+ (1,0) [0|65535] "" Vector__XXX
 SG_ INV_DateCode_MMDD : 32|16@1+ (1,0) [0|65535] "" Vector__XXX
 SG_ INV_DateCode_YYYY : 48|16@1+ (1,0) [0|65535] "" Vector__XXX

BO_ 159 M159_Diag_Data_Message: 8 INV
 SG_ INV_Diag_Record : 0|8@1+ (1,0) [0|160] "" Vector__XXX
 SG_ INV_Diag_Segment M : 8|8@1+ (1,0) [0|5] "" Vector__XXX
 SG_ INV_Diag_Gamma_Resolver m0 : 16|16@1- (0.1,0) [0|360] "angle:deg" Vector__XXX
 SG_ INV_Diag_Gamma_Observer m0 : 32|16@1- (0.1,0) [0|360] "angle:deg" Vector__XXX
 SG_ INV_Diag_Sin_Used m0 : 48|16@1- (1,0) [-5|5] "voltage:V" Vector__XXX
 SG_ INV_Diag_Cos_Used m1 : 16|16@1- (1,0) [-5|5] "voltage:V" Vector__XXX
 SG_ INV_Diag_Ia m1 : 32|16@1- (0.1,0) [-2000|2000] "current:A" Vector__XXX
 SG_ INV_Diag_Ib m1 : 48|16@1- (0.1,0) [-2000|2000] "current:A" Vector__XXX
 SG_ INV_Diag_Ic m2 : 16|16@1- (0.1,0) [-2000|2000] "current:A" Vector__XXX
 SG_ INV_Diag_Vdc m2 : 32|16@1- (0.1,0) [0|1000] "voltage:V" Vector__XXX
 SG_ INV_Diag_Iq_cmd m2 : 48|16@1- (0.1,0) [-2000|2000] "current:A" Vector__XXX
 SG_ INV_Diag_Id_cmd m3 : 16|16@1- (0.1,0) [-2000|2000] "current:A" Vector__XXX
 SG_ INV_Diag_Mod_Index m3 : 32|16@1- (0.0001,0) [0|2] "" Vector__XXX
 SG_ INV_Diag_FW_Output m3 : 48|16@1- (0.1,0) [-2000|2000] "current:A" Vector__XXX
 SG_ INV_Diag_Vq_Cmd m4 : 16|16@1- (0.1,0) [-1000|1000] "voltage:V" Vector__XXX
 SG_ INV_Diag_Vd_Cmd m4 : 32|16@1- (0.1,0) [-1000|1000] "voltage:V" Vector__XXX
 SG_ INV_Diag_Vqs_Cmd m4 : 48|16@1- (0.1,0) [-1000|1000] "voltage:V" Vector__XXX
 SG_ INV_Diag_PWM_Freq m5 : 16|16@1+ (1,0) [0|24] "frequency:kHz" Vector__XXX
 SG_ INV_Diag_Run_Faults_Lo m5 : 32|16@1+ (1,0) [0|65535] "" Vector__XXX
 SG_ INV_Diag_Run_Faults_Hi m5 : 48|16@1+ (1,0) [0|65535] "" Vector__XXX

BO_ 160 M160_Fast_Info: 8 INV
 SG_ INV_Fast_Torque_Command : 0|16@1- (0.1,0) [-3276.8|32767.7] "torque:N.m" Vector__XXX
 SG_ INV_Fast_Torque_Feedback : 16|16@1- (0.1,0) [-3276.8|3276.7] "torque:N.m" Vector__XXX
 SG_ INV_Fast_Motor_Speed : 32|16@1- (1,0) [-32768|32767] "angular_speed:rpm" Vector__XXX
 SG_ INV_Fast_DC_Bus_Voltage : 48|16@1- (0.1,0) [-3276.8|3276.7] "voltage:V" Vector__XXX

BO_ 161 M161_Torque_Capability: 8 INV
 SG_ INV_Torque_Capability : 0|16@1+ (0.1,0) [0|6553.6] "torque:N.m" Vector__XXX

BO_TX_BU_ 4 : CART,LV;

CM_ BO_ 3221225472 "This is a message for not used signals, created by Vector CANdb++ DBC OLE DB Provider.";
CM_ SG_ 157 INV_Iq_Command "The commanded Q-axis current";
CM_ SG_ 157 INV_Id_Command "The commanded D-axis current";
CM_ SG_ 157 INV_Flux_Weakening_Output "This is the current output of the flux regulator.";
CM_ SG_ 157 INV_Modulation_Index "This is the modulation index. The scale factor is x100. To get the actual modulation index divide the value by 100.";
CM_ SG_ 156 INV_Power_On_Timer "Updated every 3 msec. This will roll over in approximately 150 days!";
CM_ SG_ 156 INV_Torque_Feedback "Estimated motor torque feedback";
CM_ SG_ 156 INV_Commanded_Torque "The commanded Torque";
CM_ BO_ 178 "To write a parameter use message 0x0C1 with byte #2 set to 1 (write). 
To read a parameter use message 0x0C1 with byte #2 to set 0 (read). ";
CM_ SG_ 178 INV_Parameter_Response_Write_OK "0=Write failure, 1=Success";
CM_ SG_ 178 INV_Parameter_Response_Data "Data from parameter message.  All data is 16 bits and is contained in bytes 4 and 5. Bytes 6 and 7 should be ignored.";
CM_ SG_ 178 INV_Parameter_Response_Addr "Address of parameter response message data.";
CM_ BO_ 177 "To write a parameter use message 0x0C1 with byte #2 set to 1 (write). 
To read a parameter use message 0x0C1 with byte #2 to set 0 (read). ";
CM_ SG_ 177 VCU_INV_Parameter_Data "Data to be written.  All data is 16 bits and is contained in bytes 4 and 5.";
CM_ SG_ 177 VCU_INV_Parameter_RW_Command "0=Read, 1=Write";
CM_ SG_ 177 VCU_INV_Parameter_Address "Address of parameter to be written or read.";
CM_ BO_ 176 "The command message is used to transmit data to the controller. This message is sent from a user supplied external controller to the PMxxx controller.";
CM_ SG_ 176 VCU_INV_Inverter_Enable "0=Inverter OFF, 1 = Inverter ON";
CM_ SG_ 176 VCU_INV_Direction_Command "0=Reverse, 1=Forward.  Forward is positive motor speed.";
CM_ SG_ 176 VCU_INV_Speed_Command "Speed command used when in speed mode";
CM_ SG_ 176 VCU_INV_Torque_Command "Torque command when in torque mode";
CM_ SG_ 176 VCU_INV_Inverter_Discharge "0=Discharge Disable,1=Discharge Enable";
CM_ SG_ 176 VCU_INV_Torque_Limit_Command "Torque Limit, set to 0 to keep default";
CM_ SG_ 176 VCU_INV_Speed_Mode_Enable "0 = No change to mode, 1 = change to speed mode from torque mode";
CM_ SG_ 176 VCU_INV_Rolling_Counter "Rolling Counter sent to inverter.  If used increment count with each message sent.  Otherwise can be set to 0.";
CM_ SG_ 155 INV_Run_Fault_Hi "Each bit represents a fault. Please refer to PM100 Users Manual for details.";
CM_ SG_ 155 INV_Post_Fault_Hi "Each bit represents a fault. Please refer to PM100 Users Manual for details.";
CM_ SG_ 155 INV_Run_Fault_Lo "Each bit represents a fault. Please refer to PM100 Users Manual for details.";
CM_ SG_ 155 INV_Post_Fault_Lo "Each bit represents a fault. Please refer to PM100 Users Manual for details.";
CM_ SG_ 154 INV_Direction_Command "1 = Forward
0 = 'Reverse' if inverter enabled  & 'Stopped' if inverter is disabled";
CM_ SG_ 154 INV_Inverter_Enable_State "0=Inverter Disabled, 
1=Inverter Enabled";
CM_ SG_ 154 INV_Relay_3_Status "0=OFF, 1=ON";
CM_ SG_ 154 INV_Relay_4_Status "0=OFF, 1=ON";
CM_ SG_ 154 INV_Relay_2_Status "0=OFF, 1=ON";
CM_ SG_ 154 INV_Inverter_Run_Mode "0=Torque Mode, 1=Speed Mode";
CM_ SG_ 154 INV_Inverter_Command_Mode "0=CAN mode, 1=VSM mode";
CM_ SG_ 154 INV_Relay_1_Status "0=OFF, 1=ON";
CM_ SG_ 154 INV_Inverter_State "Different states for the inverter state machine";
CM_ SG_ 154 INV_VSM_State "Different states for the vehicle state machine";
CM_ SG_ 154 INV_Inverter_Enable_Lockout "0=Lockout Disabled, 1=Lockout Enabled";
CM_ SG_ 154 INV_Inverter_Discharge_State "0 = Disabled, 1 = Enabled, 2 = Speed Check, 3 = Active, 4 = Complete, 5 = Error, 6 = Override, 7 = Timeout";
CM_ SG_ 154 INV_Relay_5_Status "0=OFF, 1=ON";
CM_ SG_ 154 INV_Relay_6_Status "0=OFF, 1=ON";
CM_ SG_ 154 INV_BMS_Active "0 = BMS Not Active, 1 = BMS Active";
CM_ SG_ 154 INV_BMS_Torque_Limiting "0 = Not Limiting, 1 = Limiting";
CM_ SG_ 154 INV_PWM_Frequency "The current active PWM frequency";
CM_ SG_ 154 INV_Limit_Max_Speed "Indicates that torque is being modified to limit the speed.";
CM_ SG_ 154 INV_Limit_Hot_Spot "Indicates that torque is being limited to limit the hot spot temp";
CM_ SG_ 154 INV_Low_Speed_Limiting "Indicates that motor current is being limited due to low motor electrical frequency.";
CM_ SG_ 154 INV_Rolling_Counter "Rolling Counter value";
CM_ SG_ 154 INV_Limit_Coolant_Derating "0 = Not limiting, 1 = Limiting";
CM_ SG_ 154 INV_Self_Sensing_Assist_Enable "1 = Self Sensing Assist Enabled, 0 = Self Sensing Assist Disabled";
CM_ SG_ 154 INV_Limit_Stall_Burst_Model "0 = Not limiting, 1 = Limiting";
CM_ SG_ 154 INV_Burst_Model_Mode "0 = Stall, 1 = High Speed";
CM_ SG_ 154 INV_Key_Switch_Start_Status "0 = OFF, 1 = ON";
CM_ SG_ 153 INV_Ref_Voltage_12_0 "12V Input Voltage";
CM_ SG_ 153 INV_Ref_Voltage_5_0 "Transducer voltage";
CM_ SG_ 153 INV_Ref_Voltage_2_5 "Internal reference voltage";
CM_ SG_ 153 INV_Ref_Voltage_1_5 "Internal reference voltage";
CM_ SG_ 152 INV_Iq "The measured Iq current";
CM_ SG_ 152 INV_Id "The measured Id current";
CM_ SG_ 152 INV_Vq_ff "The q-axis voltage feedforward";
CM_ SG_ 152 INV_Vd_ff "The d-axis voltage feedforward";
CM_ SG_ 151 INV_VBC_Vq_Voltage "Measured value of the voltage between Phase B and Phase C";
CM_ SG_ 151 INV_VAB_Vd_Voltage "Measured value of the voltage betwen phase A and Phase B";
CM_ SG_ 151 INV_Output_Voltage "The calculated value of the output voltage, in peak line-neutral volts";
CM_ SG_ 151 INV_DC_Bus_Voltage "The actual measured value of the DC bus voltage";
CM_ SG_ 150 INV_DC_Bus_Current "The Calculated DC Bus Current";
CM_ SG_ 150 INV_Phase_C_Current "The measured value of Phase C current";
CM_ SG_ 150 INV_Phase_B_Current "The measured value of Phase B current";
CM_ SG_ 150 INV_Phase_A_Current "The measured value of Phase A current";
CM_ SG_ 149 INV_Delta_Resolver_Filtered "Used in calibration of resolver angle adjustment.";
CM_ SG_ 149 INV_Electrical_Output_Frequency "The actual electrical frequency of the inverter";
CM_ SG_ 149 INV_Motor_Speed "The measured speed of the motor";
CM_ SG_ 149 INV_Motor_Angle_Electrical "The Electrical Angle of the motor as read by the encoder or resolver";
CM_ SG_ 148 INV_Digital_Input_5 "Status of Digital Input #5";
CM_ SG_ 148 INV_Digital_Input_4 "Status of Digital Input #4";
CM_ SG_ 148 INV_Digital_Input_3 "Status of Digital Input #3";
CM_ SG_ 148 INV_Digital_Input_2 "Status of Digital Input #2";
CM_ SG_ 148 INV_Digital_Input_1 "Status of Digital Input #1";
CM_ SG_ 148 INV_Digital_Input_6 "Status of Digital Input #6";
CM_ SG_ 148 INV_Digital_Input_7 "Status of Digital Input #7";
CM_ SG_ 148 INV_Digital_Input_8 "Status of Digital Input #8";
CM_ SG_ 147 INV_Analog_Input_1 "Voltage on Analog Input #1";
CM_ SG_ 147 INV_Analog_Input_2 "Voltage on Analog Input #2";
CM_ SG_ 147 INV_Analog_Input_3 "Voltage on Analog Input #3";
CM_ SG_ 147 INV_Analog_Input_4 "Voltage on Analog Input #4";
CM_ SG_ 147 INV_Analog_Input_5 "Voltage on Analog Input #5";
CM_ SG_ 147 INV_Analog_Input_6 "Voltage on Analog Input #6";
CM_ SG_ 146 INV_Torque_Shudder "Shudder compensation value of torque";
CM_ SG_ 146 INV_Motor_Temp "Motor Temperature Sensor";
CM_ SG_ 146 INV_Hot_Spot_Temp "Estimated inverter hot spot temperature";
CM_ SG_ 146 INV_Coolant_Temp "Estimated Coolant Temperature";
CM_ SG_ 145 INV_RTD2_Temperature "RTD input 2 (PT1000) Temperature";
CM_ SG_ 145 INV_RTD1_Temperature "RTD input 1 (PT1000) Temperature";
CM_ SG_ 145 INV_Control_Board_Temp "Control Board Temperature";
CM_ SG_ 145 INV_Stall_Burst_Model_Temp "Hottest temperature estimated from the stall burst thermal model feature";
CM_ SG_ 144 INV_Gate_Driver_Board_Temp "Gate Driver Board Temperature";
CM_ SG_ 144 INV_Module_C_Temp "IGBT Module C Temperature";
CM_ SG_ 144 INV_Module_B_Temp "IGBT Module B Temperature";
CM_ SG_ 144 INV_Module_A_Temp "IGBT Module A Temperature";
CM_ BO_ 160 "To enable fast message set CAN ACTIVE MSGS HI WORD to 0xFFFE.  Setting to default value of 0xFFFF will disable the fast message.";
CM_ SG_ 160 INV_Fast_Torque_Command "The commanded torque";
CM_ SG_ 160 INV_Fast_Torque_Feedback "The estimated torque";
CM_ SG_ 160 INV_Fast_Motor_Speed "Motor speed";
CM_ SG_ 160 INV_Fast_DC_Bus_Voltage "DC Bus Voltage";
CM_ SG_ 161 INV_Torque_Capability "The torque capability of the inverter given the current operating point.";
BA_DEF_ BO_  "GenMsgCycleTime" INT 0 100000;
BA_DEF_  "BusType" STRING ;
BA_DEF_DEF_  "GenMsgCycleTime" 0;
BA_DEF_DEF_  "BusType" "CAN";
BA_ "GenMsgCycleTime" BO_ 156 10;
BA_ "GenMsgCycleTime" BO_ 176 10;
BA_ "GenMsgCycleTime" BO_ 155 100;
BA_ "GenMsgCycleTime" BO_ 154 100;
BA_ "GenMsgCycleTime" BO_ 153 100;
BA_ "GenMsgCycleTime" BO_ 152 10;
BA_ "GenMsgCycleTime" BO_ 151 10;
BA_ "GenMsgCycleTime" BO_ 150 10;
BA_ "GenMsgCycleTime" BO_ 149 10;
BA_ "GenMsgCycleTime" BO_ 148 10;
BA_ "GenMsgCycleTime" BO_ 147 10;
BA_ "GenMsgCycleTime" BO_ 146 100;
BA_ "GenMsgCycleTime" BO_ 145 100;
BA_ "GenMsgCycleTime" BO_ 144 100;
BA_ "GenMsgCycleTime" BO_ 160 3;
BA_ "GenMsgCycleTime" BO_ 161 10;
VAL_ 176 VCU_INV_Inverter_Enable 0 "Turn the inverter OFF" 1 "Turn the Inverter ON" ;
VAL_ 176 VCU_INV_Direction_Command 0 "CW" 1 "CCW" ;
VAL_ 176 VCU_INV_Inverter_Discharge 0 "Discharge Disable" 1 "Discharge Enable (if EEPROM parameter is set)" ;
VAL_ 154 INV_Inverter_State 0 "Power up" 1 "Stop" 2 "Open Loop" 3 "Closed Loop" 4 "Internal State" 5 "Internal State" 6 "Internal State" 7 "Internal State" 8 "Idle Run" 9 "Idle Stop" 10 "Internal State" 11 "Intern State" 12 "Internal State" ;
VAL_ 154 INV_VSM_State 0 "VSM Start State" 1 "Pre-Charge Init state" 2 "pre-charge active state" 3 "pre-charge complete state" 4 "VSM wait state" 5 "VSM ready state" 6 "Motor Running State" 7 "blink fault code state" 14 "Shutdown state for Key Switch Mode 1" 15 "Reset the inverter" ;
VAL_ 154 INV_Inverter_Discharge_State 0 "Disabled" 1 "Enabled" 2 "Speed Check" 3 "Active" 4 "Complete" 5 "Error" 6 "Override" 7 "Timeout" ;
VAL_ 154 INV_Limit_Stall_Burst_Model 0 "Not Limiting" 1 "Limiting" ;
VAL_ 154 INV_Burst_Model_Mode 0 "Stall" 1 "High Speed" ;
